# DSS_CM4_CTRL register map
Vendor: Texas Instruments
Peripheral module from a debugger description file (folder awr2x44p).
Registers are 32-bit, read-write, no defined reset value unless marked. A register's access mark holds for its fields unless they carry their own. Offsets are as the file gives them; lines under a group give offsets from that group; [hi:lo] are bit positions; {n}, {i} and the like mark numbered series; 'fields as' and 'values as' point back to an identical list; <NAME> marks a mode.

## DSS_CM4_CTRL
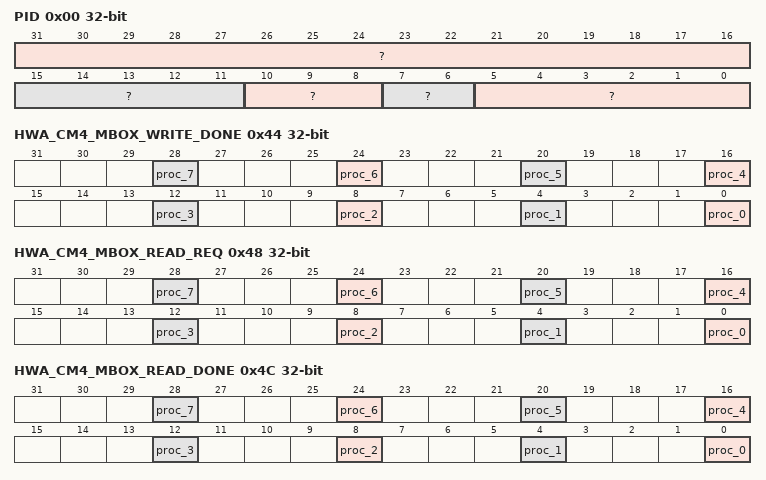
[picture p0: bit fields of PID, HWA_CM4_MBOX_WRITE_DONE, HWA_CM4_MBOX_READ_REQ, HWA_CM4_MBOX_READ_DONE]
0x00 PID ro
  [31:16] ?, [15:11] ?, [10:8] ?, [7:6] ?, [5:0] ?
0x04 HW_REG0
  [31:0] hwreg0 — Reserved for HW R&D
0x08 HW_REG1
  [31:0] hwreg1 — Reserved for HW R&D
0x0C PREVIOUS_NAME
  [31:0] hwreg2 — Reserved for HW R&D
0x10 HW_REG3
  [31:0] hwreg3 — Reserved for HW R&D
0x14 HWA_CM4_B0_MEMINIT_START
  [0] hwa_cm4_b0_meminit_start — Write pulse bit field: Start Memory intialization of Param memory. Write 0x1 to start memory initilization.
{0x18+0xC*i} HWA_CM4_B{i}_MEMINIT_STATUS ro (i=0..2)
  [0] hwa_cm4_b{i}_meminit_status — Status field. Read value 0x1 indicates previously triggered Memory intialization of Param memory is in progress.
{0x1C+0xC*i} HWA_CM4_B{i}_MEMINIT_DONE (i=0..2)
  [0] hwa_cm4_b{i}_meminit_done — Rising Edge Capture reg (write 1 to clear): Status field. Read value 0x1 indicates previously triggered Memory intialization of Param memory is complte. Write 0x1 to clear status. Refer Memory initialization sequnce in EDMA section for more details
0x20 HWA_CM4_B1_MEMINIT_START
  [0] hwa_cm4_b1_meminit_start — Write pulse bit field: Write pulse bit field:Start Memory intialization of Param memory. Write 0x1 to start memory initilization.
0x2C HWA_CM4_B2_MEMINIT_START
  [0] hwa_cm4_b2_meminit_start — Write pulse bit field: Start Memory intialization of Param memory. Write 0x1 to start memory initilization.
0x38 HWA_CM4_MBOX_MEMINIT_START
  [0] hwa_cm4_mbox_meminit_start — Write pulse bit field: Start Memory intialization of Param memory. Write 0x1 to start memory initilization.
0x3C HWA_CM4_MBOX_MEMINIT_STATUS ro
  [0] hwa_cm4_mbox_meminit_status — Status field. Read value 0x1 indicates previously triggered Memory intialization of Param memory is in progress.
0x40 HWA_CM4_MBOX_MEMINIT_DONE
  [0] hwa_cm4_mbox_meminit_done — Rising Edge Capture reg (write 1 to clear): Status field. Read value 0x1 indicates previously triggered Memory intialization of Param memory is complte. Write 0x1 to clear status. Refer Memory initialization sequnce in EDMA section for more details
0x44 HWA_CM4_MBOX_WRITE_DONE
  [4n] proc_{n} (n=0..7) — Write pulse bit field: This register should be written once finishing writing into the mailbox memory of processor {n}
0x48 HWA_CM4_MBOX_READ_REQ
  [4n] proc_{n} (n=0..7) — Rising Edge Capture reg (write 1 to clear): This is request from processor {n} to HSM. Requesting it to read from mailbox.
0x4C HWA_CM4_MBOX_READ_DONE
  [4n] proc_{n} (n=0..7) — Rising Edge Capture reg (write 1 to clear): This register should be written once finishing reading from hsm's mailbox written by proc {n}
0x50 HWA_CM4_IRQ_REQ
  [1:0] select — Write pulse bit field: Software configration for INT Request
0x54 HWA_CM4_POR_RST_CTRL
  [2:0] assert — Write pulse bit field: Por reset control for CM4
0x58 HWA_CM4_SYS_RST_CTRL
  [2:0] assert — Write pulse bit field: Reset control for CM4
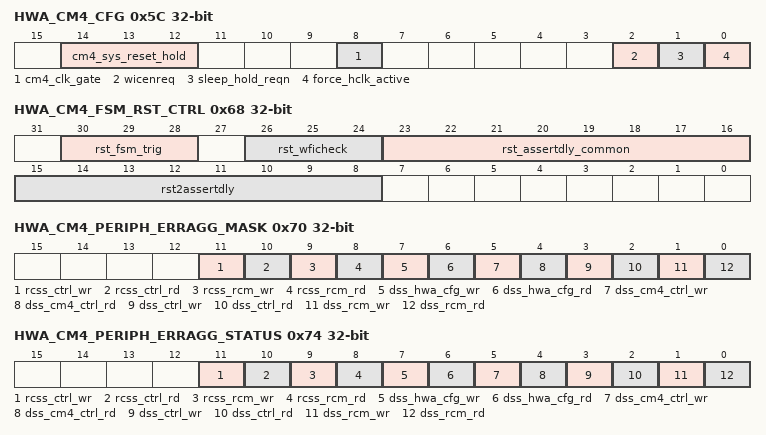
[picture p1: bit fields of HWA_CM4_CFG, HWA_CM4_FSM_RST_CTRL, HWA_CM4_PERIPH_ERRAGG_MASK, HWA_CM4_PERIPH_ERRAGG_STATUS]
0x5C HWA_CM4_CFG
  [14:12] cm4_sys_reset_hold — In development mode by default cm4 will be held in reset. Writing 3'b000 will remove it from reset.
  [8] cm4_clk_gate — CM4 Clock Gate. 0 : Un-gate the clock, 1 : Clock gated.
  [2] wicenreq — WIC mode Request from PMU
  [1] sleep_hold_reqn — Hold core in sleep mode. '0' : When in sleep mode, enable continue to hold the core in sleep; '1' : This feature is disabled
  [0] force_hclk_active — Force HCLK to run , overrides GATEHCLK
0x60 HWA_CM4_RST_CAUSE_CLR
  [2:0] clear — Write pulse bit field: Writing '111' will clear the HWA_CM4_RST_STATUS_REG
0x64 HWA_CM4_RST_CAUSE ro
  [7:0] status — Reset Cause Register. Value of 1'b1 indicates reset from different sources. [0 ] : POR_RSTN, [1 ] : SYS_RSTN (Warm reset), [2 ] : STC Reset, [3 ] : Register HWA_CM4_POR_RST_CTRL, [4 ] : Register HWA_CM4_SYS_RST_CTRL, [5 ] : Reset trigger from GSM, [7:6] : Reserved
0x68 HWA_CM4_FSM_RST_CTRL
  [30:28] rst_fsm_trig — Write pulse bit field: writing '111' will triggger the reset fsm for CM4
  [26:24] rst_wficheck — writing '111' will check for WFI before asserting reset to CM4
  [23:16] rst_assertdly_common — This field the decides number of cycles reset to CM4 should be asserted
  [15:8] rst2assertdly — This field the decides number cycles for which the reset should be held before asserting reset for CM4. This register should be programmed only for debug, otherwise the value should be 8'h00.
0x6C HWA_CM4_WFI_OVERRIDE
  [2:0] wfi_override — writing '111' will override the wfi signal from CM4
0x70 HWA_CM4_PERIPH_ERRAGG_MASK
  [11] rcss_ctrl_wr — Writing '1' will mask the respective peripheral error line
  [10] rcss_ctrl_rd — Writing '1' will mask the respective peripheral error line
  [9] rcss_rcm_wr — Writing '1' will mask the respective peripheral error line
  [8] rcss_rcm_rd — Writing '1' will mask the respective peripheral error line
  [7] dss_hwa_cfg_wr — Writing '1' will mask the respective peripheral error line
  [6] dss_hwa_cfg_rd — Writing '1' will mask the respective peripheral error line
  [5] dss_cm4_ctrl_wr — Writing '1' will mask the respective peripheral error line
  [4] dss_cm4_ctrl_rd — Writing '1' will mask the respective peripheral error line
  [3] dss_ctrl_wr — Writing '1' will mask the respective peripheral error line
  [2] dss_ctrl_rd — Writing '1' will mask the respective peripheral error line
  [1] dss_rcm_wr — Writing '1' will mask the respective peripheral error line
  [0] dss_rcm_rd — Writing '1' will mask the respective peripheral error line
0x74 HWA_CM4_PERIPH_ERRAGG_STATUS
  [11] rcss_ctrl_wr — Rising Edge Capture reg (write 1 to clear): Indicates the post mask status of the respective peripheral error line
  [10] rcss_ctrl_rd — Rising Edge Capture reg (write 1 to clear): Indicates the post mask status of the respective peripheral error line
  [9] rcss_rcm_wr — Rising Edge Capture reg (write 1 to clear): Indicates the post mask status of the respective peripheral error line
  [8] rcss_rcm_rd — Rising Edge Capture reg (write 1 to clear): Indicates the post mask status of the respective peripheral error line
  [7] dss_hwa_cfg_wr — Rising Edge Capture reg (write 1 to clear): Indicates the post mask status of the respective peripheral error line
  [6] dss_hwa_cfg_rd — Rising Edge Capture reg (write 1 to clear): Indicates the post mask status of the respective peripheral error line
  [5] dss_cm4_ctrl_wr — Rising Edge Capture reg (write 1 to clear): Indicates the post mask status of the respective peripheral error line
  [4] dss_cm4_ctrl_rd — Rising Edge Capture reg (write 1 to clear): Indicates the post mask status of the respective peripheral error line
  [3] dss_ctrl_wr — Rising Edge Capture reg (write 1 to clear): Indicates the post mask status of the respective peripheral error line
  [2] dss_ctrl_rd — Rising Edge Capture reg (write 1 to clear): Indicates the post mask status of the respective peripheral error line
  [1] dss_rcm_wr — Rising Edge Capture reg (write 1 to clear): Indicates the post mask status of the respective peripheral error line
  [0] dss_rcm_rd — Rising Edge Capture reg (write 1 to clear): Indicates the post mask status of the respective peripheral error line
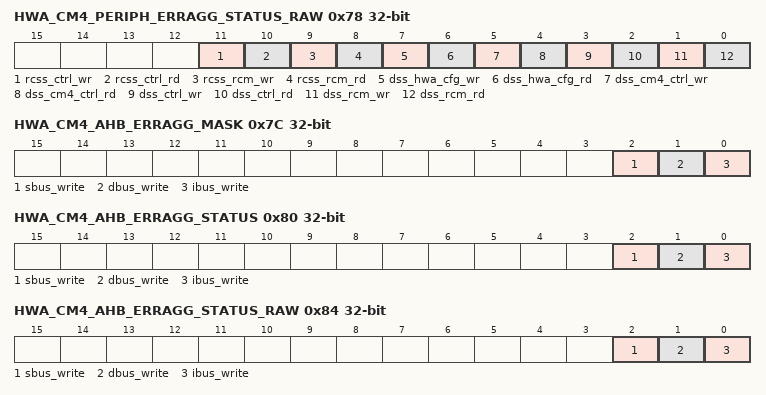
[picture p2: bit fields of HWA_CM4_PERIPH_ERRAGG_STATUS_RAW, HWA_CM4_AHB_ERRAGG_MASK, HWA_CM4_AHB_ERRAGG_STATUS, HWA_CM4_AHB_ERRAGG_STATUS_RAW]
0x78 HWA_CM4_PERIPH_ERRAGG_STATUS_RAW
  [11] rcss_ctrl_wr — Rising Edge Capture reg (write 1 to clear): Indicates the pre mask status of the respective peripheral error line
  [10] rcss_ctrl_rd — Rising Edge Capture reg (write 1 to clear): Indicates the pre mask status of the respective peripheral error line
  [9] rcss_rcm_wr — Rising Edge Capture reg (write 1 to clear): Indicates the pre mask status of the respective peripheral error line
  [8] rcss_rcm_rd — Rising Edge Capture reg (write 1 to clear): Indicates the pre mask status of the respective peripheral error line
  [7] dss_hwa_cfg_wr — Rising Edge Capture reg (write 1 to clear): Indicates the pre mask status of the respective peripheral error line
  [6] dss_hwa_cfg_rd — Rising Edge Capture reg (write 1 to clear): Indicates the pre mask status of the respective peripheral error line
  [5] dss_cm4_ctrl_wr — Rising Edge Capture reg (write 1 to clear): Indicates the pre mask status of the respective peripheral error line
  [4] dss_cm4_ctrl_rd — Rising Edge Capture reg (write 1 to clear): Indicates the pre mask status of the respective peripheral error line
  [3] dss_ctrl_wr — Rising Edge Capture reg (write 1 to clear): Indicates the pre mask status of the respective peripheral error line
  [2] dss_ctrl_rd — Rising Edge Capture reg (write 1 to clear): Indicates the pre mask status of the respective peripheral error line
  [1] dss_rcm_wr — Rising Edge Capture reg (write 1 to clear): Indicates the pre mask status of the respective peripheral error line
  [0] dss_rcm_rd — Rising Edge Capture reg (write 1 to clear): Indicates the pre mask status of the respective peripheral error line
0x7C HWA_CM4_AHB_ERRAGG_MASK
  [2] sbus_write — Writing '1' will mask the respective peripheral error line
  [1] dbus_write — Writing '1' will mask the respective peripheral error line
  [0] ibus_write — Writing '1' will mask the respective peripheral error line
0x80 HWA_CM4_AHB_ERRAGG_STATUS
  [2] sbus_write — Rising Edge Capture reg (write 1 to clear): Indicates the post mask status of the respective peripheral error line
  [1] dbus_write — Rising Edge Capture reg (write 1 to clear): Indicates the post mask status of the respective peripheral error line
  [0] ibus_write — Rising Edge Capture reg (write 1 to clear): Indicates the post mask status of the respective peripheral error line
0x84 HWA_CM4_AHB_ERRAGG_STATUS_RAW
  [2] sbus_write — Rising Edge Capture reg (write 1 to clear): Indicates the pre mask status of the respective peripheral error line
  [1] dbus_write — Rising Edge Capture reg (write 1 to clear): Indicates the pre mask status of the respective peripheral error line
  [0] ibus_write — Rising Edge Capture reg (write 1 to clear): Indicates the pre mask status of the respective peripheral error line
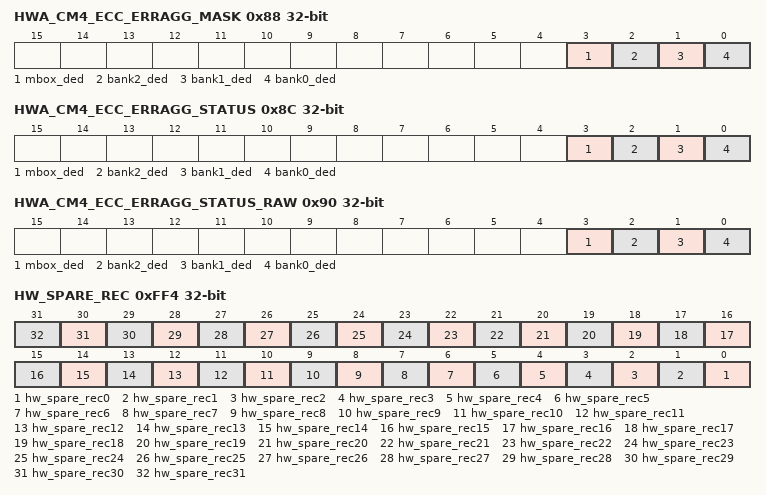
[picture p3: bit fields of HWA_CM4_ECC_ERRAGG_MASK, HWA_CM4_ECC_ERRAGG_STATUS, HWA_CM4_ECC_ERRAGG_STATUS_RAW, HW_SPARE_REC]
0x88 HWA_CM4_ECC_ERRAGG_MASK
  [3] mbox_ded — Writing '1' will mask the respective peripheral error line
  [2] bank2_ded — Writing '1' will mask the respective peripheral error line
  [1] bank1_ded — Writing '1' will mask the respective peripheral error line
  [0] bank0_ded — Writing '1' will mask the respective peripheral error line
0x8C HWA_CM4_ECC_ERRAGG_STATUS
  [3] mbox_ded — Rising Edge Capture reg (write 1 to clear): Indicates the post mask status of the respective peripheral error line
  [2] bank2_ded — Rising Edge Capture reg (write 1 to clear): Indicates the post mask status of the respective peripheral error line
  [1] bank1_ded — Rising Edge Capture reg (write 1 to clear): Indicates the post mask status of the respective peripheral error line
  [0] bank0_ded — Rising Edge Capture reg (write 1 to clear): Indicates the post mask status of the respective peripheral error line
0x90 HWA_CM4_ECC_ERRAGG_STATUS_RAW
  [3] mbox_ded — Rising Edge Capture reg (write 1 to clear): Indicates the pre mask status of the respective peripheral error line
  [2] bank2_ded — Rising Edge Capture reg (write 1 to clear): Indicates the pre mask status of the respective peripheral error line
  [1] bank1_ded — Rising Edge Capture reg (write 1 to clear): Indicates the pre mask status of the respective peripheral error line
  [0] bank0_ded — Rising Edge Capture reg (write 1 to clear): Indicates the pre mask status of the respective peripheral error line
{0xFD0+4i} HW_SPARE_RW{i} (i=0..3)
  [31:0] hw_spare_rw{i} — Reserved for HW R&D
{0xFE0+4i} HW_SPARE_RO{i} ro (i=0..3)
  [31:0] hw_spare_ro{i} — Reserved for HW R&D
0xFF0 HW_SPARE_WPH
  [31:0] proc — Write pulse bit field: For bits 0 to 7: Wrting 1'b1 : Generates pulse interrupt to corresponding proc from HWA_CM4.
0xFF4 HW_SPARE_REC
  [n] hw_spare_rec{n} (n=0..31) — Rising Edge Capture reg (write 1 to clear): Reserved for HW R&D
0x1008 LOCK0_KICK0 — - KICK0 component
  [31:0] ?
0x100C LOCK0_KICK1 — - KICK1 component
  [31:0] ?
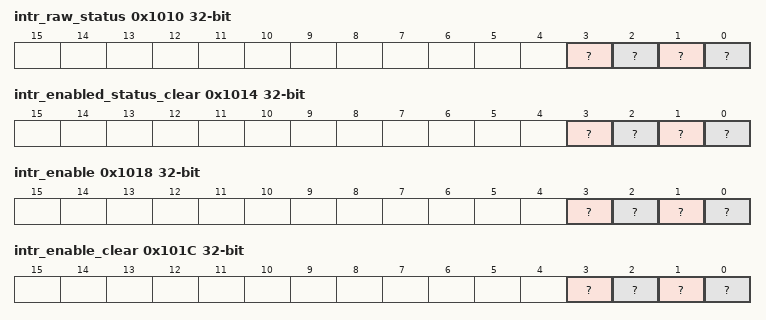
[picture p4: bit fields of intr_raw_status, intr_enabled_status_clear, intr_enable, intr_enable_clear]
0x1010 intr_raw_status — Interrupt Raw Status/Set Register
  [3] ? — Proxy0 access violation error. Raw status is read. Write a 1 to set the status. Writing a 0 has no effect.
  [2] ? — Kick access violation error. Raw status is read. Write a 1 to set the status. Writing a 0 has no effect.
  [1] ? — Addressing violation error. Raw status is read. Write a 1 to set the status. Writing a 0 has no effect.
  [0] ? — Protection violation error. Raw status is read. Write a 1 to set the status. Writing a 0 has no effect.
0x1014 intr_enabled_status_clear — Interrupt Enabled Status/Clear register
  [3] ? — Proxy0 access violation error. Enabled status is read. Write a 1 to clear the status. Writing a 0 has no effect.
  [2] ? — Kick access violation error. Enabled status is read. Write a 1 to clear the status. Writing a 0 has no effect.
  [1] ? — Addressing violation error. Enabled status is read. Write a 1 to clear the status. Writing a 0 has no effect.
  [0] ? — Protection violation error. Enabled status is read. Write a 1 to clear the status. Writing a 0 has no effect.
0x1018 intr_enable — Interrupt Enable register
  [3] ? — Proxy0 access violation error enable. Write a 1 to set the enable. Writing a 0 has no effect.
  [2] ? — Kick access violation error enable. Write a 1 to set the enable. Writing a 0 has no effect.
  [1] ? — Addressing violation error enable. Write a 1 to set the enable. Writing a 0 has no effect.
  [0] ? — Protection violation error enable. Write a 1 to set the enable. Writing a 0 has no effect.
0x101C intr_enable_clear — Interrupt Enable Clear register
  [3] ? — Proxy0 access violation error enable clear. Write a 1 to clear the enable. Writing a 0 has no effect.
  [2] ? — Kick access violation error enable clear. Write a 1 to clear the enable. Writing a 0 has no effect.
  [1] ? — Addressing violation error enable clear. Write a 1 to clear the enable. Writing a 0 has no effect.
  [0] ? — Protection violation error enable clear. Write a 1 to clear the enable. Writing a 0 has no effect.
0x1020 eoi
  [7:0] ? — EOI vector value. Write this with interrupt distribution value in the chip.
0x1024 fault_address ro
  [31:0] ? — Fault Address.
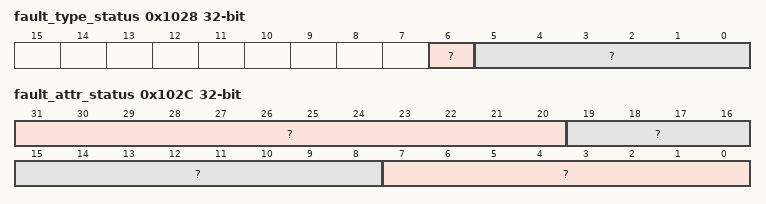
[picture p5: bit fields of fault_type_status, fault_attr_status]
0x1028 fault_type_status ro
  [6] ? — Non-secure access.
  [5:0] ? — Fault Type 10_0000 = Supervisor read fault - priv = 1 dir = 1 dtype != 1 01_0000 = Supervisor write fault - priv = 1 dir = 0 00_1000 = Supervisor execute fault - priv = 1 dir = 1 dtype = 1 00_0100 = User read fault - priv = 0 dir = 1 dtype = 1 00_0010 = User write fault - priv = 0 dir = 0 00_0001 = User execute fault - priv = 0 dir = 1 dtype = 1 00_0000 = No fault
0x102C fault_attr_status ro — Fault Attribute Status register
  [31:20] ? — XID.
  [19:8] ? — Route ID.
  [7:0] ? — Privilege ID.
0x1030 fault_clear wo
  [0] ? — Fault clear. Writing a 1 clears the current fault. Writing a 0 has no effect.
